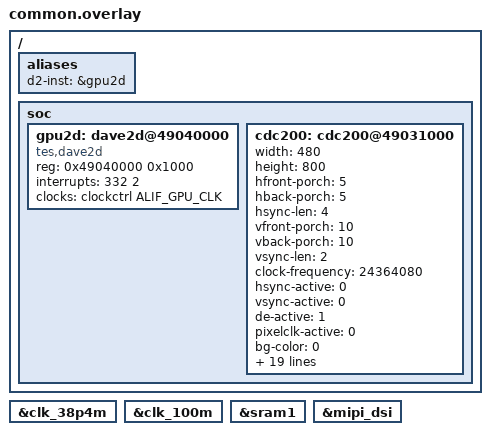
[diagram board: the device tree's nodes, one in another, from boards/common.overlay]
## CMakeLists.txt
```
# SPDX-License-Identifier: Apache-2.0

cmake_minimum_required(VERSION 3.20.0)

set(DTC_OVERLAY_FILE
    "../../../boards/arm/alif_e7_devkit/alif_e7_dk_rtss_he_hp_dave2d.overlay"
    "boards/alif_serial_display.overlay"
)

find_package(Zephyr REQUIRED HINTS $ENV{ZEPHYR_BASE})
project(aipl_example)

add_subdirectory(
    ../../../lib/aipl
    ${CMAKE_BINARY_DIR}/lib/aipl
)

# Add include directories
zephyr_include_directories(
    ../common/assets
    ../common/display/
    src/graphics/
)

# Add app sources
target_sources(app PRIVATE
    ../common/cache.c
    ../common/video_alloc.c
    ../common/display/display.c
    src/graphics/image.c
    src/main.c
)

# Link AIPL with the app
target_link_libraries(app PRIVATE aipl)

if (NOT CONFIG_AIPL_DAVE2D_ACCELERATION)
    # Add D/AVE2D functions directly to be able to use it
    target_sources(app PRIVATE ../../../lib/aipl/source/aipl_dave2d.c)
endif()

# Add asset files to the app
target_sources(app PRIVATE
    ../common/assets/sample_photo_alpha8.c
    ../common/assets/sample_photo_argb1555.c
    ../common/assets/sample_photo_argb4444.c
    ../common/assets/sample_photo_argb8888.c
    ../common/assets/sample_photo_rgb565.c
    ../common/assets/sample_photo_rgb888.c
    ../common/assets/sample_photo_rgba4444.c
    ../common/assets/sample_photo_rgba5551.c
    ../common/assets/sample_photo_rgba8888.c
)
```

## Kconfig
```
# Copyright(C) 2025 Alif Semiconductor - All Rights Reserved.
# Use, distribution and modification of this code is permitted under the
# terms stated in the Alif Semiconductor Software License Agreement
#
# You should have received a copy of the Alif Semiconductor Software
# License Agreement with this file.If not, please write to:
# contact @alifsemi.com, or visit : https: // alifsemi.com/license

source "../alif/lib/aipl/Kconfig"
source "Kconfig.zephyr"
```

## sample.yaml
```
sample:
  name: Alif Image Processing Library demo
  common:
    modules:
      - aipl
      - dave2d
```

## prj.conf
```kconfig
CONFIG_AIPL=y
CONFIG_DAVE2D=y

CONFIG_MIPI_DSI=y
CONFIG_DISPLAY=y
CONFIG_HEAP_MEM_POOL_SIZE=16384

CONFIG_MAIN_STACK_SIZE=2048

CONFIG_IMG_ASSETS=y
CONFIG_DBUF_DISPLAY=y
CONFIG_DBUF_DISPLAY_SECTION=".alif_sram0"
CONFIG_D0_HEAP_SECTION=".alif_sram1"
CONFIG_IMG_CNV_SECTION=".alif_sram0"

CONFIG_LOG=y
```

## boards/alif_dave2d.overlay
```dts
/* Copyright (C) 2024 Alif Semiconductor - All Rights Reserved.
 * Use, distribution and modification of this code is permitted under the
 * terms stated in the Alif Semiconductor Software License Agreement
 *
 * You should have received a copy of the Alif Semiconductor Software
 * License Agreement with this file. If not, please write to:
 * contact@alifsemi.com, or visit: https://alifsemi.com/license
 *
 */

/ {
	soc {
		gpu2d: dave2d@49040000 {
            compatible = "tes,dave2d";
            reg = < 0x49040000 0x1000 >;
            interrupts = < 332 2 >;
            clocks = < &clock ALIF_GPU_CLK >;
        };
	};

    aliases {
        d2-inst = &gpu2d;
    };
};
```

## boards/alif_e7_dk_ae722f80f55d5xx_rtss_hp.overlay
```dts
/* Copyright (C) Alif Semiconductor - All Rights Reserved.
 * Use, distribution and modification of this code is permitted under the
 * terms stated in the Alif Semiconductor Software License Agreement
 *
 * You should have received a copy of the Alif Semiconductor Software
 * License Agreement with this file. If not, please write to:
 * contact@alifsemi.com, or visit: https://alifsemi.com/license
 *
 */

#include "common.overlay"
```

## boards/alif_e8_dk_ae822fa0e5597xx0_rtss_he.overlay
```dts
/* Copyright (C) Alif Semiconductor - All Rights Reserved.
 * Use, distribution and modification of this code is permitted under the
 * terms stated in the Alif Semiconductor Software License Agreement
 *
 * You should have received a copy of the Alif Semiconductor Software
 * License Agreement with this file. If not, please write to:
 * contact@alifsemi.com, or visit: https://alifsemi.com/license
 *
 */

#include "common.overlay"

&gpio14 {
	status = "okay";
};
```

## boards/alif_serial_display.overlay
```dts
/* Copyright (C) 2025 Alif Semiconductor - All Rights Reserved.
 * Use, distribution and modification of this code is permitted under the
 * terms stated in the Alif Semiconductor Software License Agreement
 *
 * You should have received a copy of the Alif Semiconductor Software
 * License Agreement with this file. If not, please write to:
 * contact@alifsemi.com, or visit: https://alifsemi.com/license
 *
 */

/ {
	soc {
		cdc200: cdc200@49031000 {
			width = <480>;
			height = <800>;
			hfront-porch = <5>;
			hback-porch = <5>;
			hsync-len = <4>;
			vfront-porch = <10>;
			vback-porch = <10>;
			vsync-len = <2>;
			clock-frequency = <24364080>;
			hsync-active = <0>;
			vsync-active = <0>;
			de-active = <1>;
			pixelclk-active = <0>;
			bg-color = <0>;
			enable-l1 = <1>;
			pixel-fmt-l1 = "rgb-565";
			def-back-color-l1 = <0>;
			win-x0-l1 = <0>;
			win-y0-l1 = <0>;
			win-x1-l1 = <480>;
			win-y1-l1 = <800>;
			blend-factor1-l1 = <4>;
			blend-factor2-l1 = <5>;
			const-alpha-l1 = <0xff>;
			enable-l2 = <0>;
			pixel-fmt-l2 = "undefined";
			win-x0-l2 = <0>;
			win-y0-l2 = <0>;
			win-x1-l2 = <0>;
			win-y1-l2 = <0>;
			blend-factor1-l2 = <6>;
			blend-factor2-l2 = <7>;
			const-alpha-l2 = <0xff>;
		};
	};
};

&mipi_dsi {
	status = "okay";
};
```

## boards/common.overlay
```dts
/* Copyright (C) Alif Semiconductor - All Rights Reserved.
 * Use, distribution and modification of this code is permitted under the
 * terms stated in the Alif Semiconductor Software License Agreement
 *
 * You should have received a copy of the Alif Semiconductor Software
 * License Agreement with this file. If not, please write to:
 * contact@alifsemi.com, or visit: https://alifsemi.com/license
 *
 */

/ {
	aliases {
		d2-inst = &gpu2d;
	};

	soc {
		gpu2d: dave2d@49040000 {
			compatible = "tes,dave2d";
			reg = <0x49040000 0x1000>;
			interrupts = <332 2>;
			clocks = <&clockctrl ALIF_GPU_CLK>;
		};

		cdc200: cdc200@49031000 {
			width = <480>;
			height = <800>;
			hfront-porch = <5>;
			hback-porch = <5>;
			hsync-len = <4>;
			vfront-porch = <10>;
			vback-porch = <10>;
			vsync-len = <2>;
			clock-frequency = <24364080>;
			hsync-active = <0>;
			vsync-active = <0>;
			de-active = <1>;
			pixelclk-active = <0>;
			bg-color = <0>;
			enable-l1 = <1>;
			pixel-fmt-l1 = "rgb-565";
			def-back-color-l1 = <0>;
			win-x0-l1 = <0>;
			win-y0-l1 = <0>;
			win-x1-l1 = <480>;
			win-y1-l1 = <800>;
			blend-factor1-l1 = <4>;
			blend-factor2-l1 = <5>;
			const-alpha-l1 = <0xff>;
			enable-l2 = <0>;
			pixel-fmt-l2 = "undefined";
			win-x0-l2 = <0>;
			win-y0-l2 = <0>;
			win-x1-l2 = <0>;
			win-y1-l2 = <0>;
			blend-factor1-l2 = <6>;
			blend-factor2-l2 = <7>;
			const-alpha-l2 = <0xff>;
		};
	};
};

&clk_38p4m {
	status = "okay";
};

&clk_100m {
	status = "okay";
};

&sram1 {
	status = "okay";
};

&mipi_dsi {
	status = "okay";
};
```

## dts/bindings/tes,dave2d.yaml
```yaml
# Copyright (C) 2025 Alif Semiconductor
# SPDX-License-Identifier: Apache-2.0

description: TES D/AVE2D graphics IP core

compatible: "tes,dave2d"

include: [base.yaml]

properties:
  reg:
    required: true

  interrupts:
    required: true

  clocks:
    required: true
```

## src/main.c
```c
/* Copyright (C) Alif Semiconductor - All Rights Reserved.
 * Use, distribution and modification of this code is permitted under the
 * terms stated in the Alif Semiconductor Software License Agreement
 *
 * You should have received a copy of the Alif Semiconductor Software
 * License Agreement with this file. If not, please write to:
 * contact@alifsemi.com, or visit: https://alifsemi.com/license
 *
 */

#include <dave_d0lib.h>
#include <aipl_dave2d.h>
#include <aipl_color_conversion.h>
#include <aipl_color_correction.h>
#include <aipl_white_balance.h>
#include <aipl_lut_transform.h>
#include <aipl_crop.h>
#include <aipl_resize.h>
#include <aipl_rotate.h>
#include <aipl_flip.h>
#include <aipl_utils.h>

#include <math.h>

#include "image.h"
#include "img_assets/assets.h"
#include "dbuf_display/display.h"

#include <soc_common.h>
#include <se_service.h>

#include <zephyr/kernel.h>
#include <zephyr/drivers/gpio.h>
#include <zephyr/drivers/display.h>
#include <zephyr/logging/log.h>
LOG_MODULE_REGISTER(app, CONFIG_LOG_DEFAULT_LEVEL);

#define D1_HEAP_SIZE 0x180000

#ifdef CONFIG_D0_HEAP_SECTION
#define D0_HEAP_ATTRS __attribute__((section(CONFIG_D0_HEAP_SECTION)))
#else
#define D0_HEAP_ATTRS
#endif

static uint8_t D0_HEAP_ATTRS d0_heap[D1_HEAP_SIZE];

static void display_panel_on(void)
{
#if DT_HAS_ALIAS(panel) && DT_NODE_HAS_STATUS(DT_ALIAS(panel), okay)
	const struct device *panel = DEVICE_DT_GET(DT_ALIAS(panel));

	if (!device_is_ready(panel)) {
		LOG_WRN("Display panel device not ready");
		return;
	}

	int ret = display_blanking_off(panel);

	if (ret) {
		LOG_WRN("Display panel enable failed (%d), continuing", ret);
	}
#endif
}

static void crop_scale_example(void)
{
	/* Prepare the source image */
	const image_t *test_img = &SAMPLE_PHOTO_ARGB8888;
	const aipl_image_t src_image = {test_img->data, test_img->pitch, test_img->width,
					test_img->height, test_img->format};

	/* Prepare the destination image for cropping */
	uint32_t p = src_image.pitch / 4;
	uint32_t w = src_image.width / 4;
	uint32_t h = src_image.height / 4;
	aipl_image_t cropped_image;

	aipl_image_create(&cropped_image, p, w, h, src_image.format);

	/* Crop the source image using the specified rectangular area */
	uint32_t x = 200;
	uint32_t y = 100;

	aipl_crop_img(&src_image, &cropped_image, x, y, x + w, y + h);

	/* Prepare the destination image for scaling */
	aipl_image_t scaled_image;

	aipl_image_create(&scaled_image, p * 3, w * 3, h * 3, cropped_image.format);

	/* Scale up the cropped image appliying linear interpolation */
	aipl_resize_img(&cropped_image, &scaled_image, true);

	/* Prepare DAVE2D for image rendering */
	aipl_dave2d_prepare();

	/* Draw source and destination images */
	aipl_image_draw(0, 20, &src_image);
	aipl_image_draw(0, 400, &cropped_image);
	aipl_image_draw(0, 500, &scaled_image);

	/* Execute HW rendering */
	aipl_dave2d_render();

	/* Release the memory occupied by the destination images */
	aipl_image_destroy(&cropped_image);
	aipl_image_destroy(&scaled_image);
}

static void crop_flip_example(void)
{
	/* Prepare the source image */
	const image_t *test_img = &SAMPLE_PHOTO_ARGB8888;
	const aipl_image_t src_image = {test_img->data, test_img->pitch, test_img->width,
					test_img->height, test_img->format};

	/* Prepare the destination image for cropping */
	uint32_t p = src_image.pitch / 2;
	uint32_t w = src_image.width / 2;
	uint32_t h = src_image.height / 2;
	aipl_image_t cropped_image;

	aipl_image_create(&cropped_image, p, w, h, src_image.format);

	/* Crop the source image using the specified rectangular area */
	uint32_t x = 200;
	uint32_t y = 100;

	aipl_crop_img(&src_image, &cropped_image, x, y, x + w, y + h);

	/* Prepare the destination image for flipping */
	aipl_image_t flipped_image;

	aipl_image_create(&flipped_image, p, w, h, cropped_image.format);

	/* Flip the image horizontally and vertically */
	aipl_flip_img(&cropped_image, &flipped_image, true, true);

	/* Prepare DAVE2D for image rendering */
	aipl_dave2d_prepare();

	/* Draw source and destination images */
	aipl_image_draw(0, 20, &src_image);
	aipl_image_draw(0, 400, &cropped_image);
	aipl_image_draw(0, 600, &flipped_image);

	/* Execute HW rendering */
	aipl_dave2d_render();

	/* Release the memory occupied by the destination images */
	aipl_image_destroy(&cropped_image);
	aipl_image_destroy(&flipped_image);
}

static void scale_rotate_example(void)
{
	/* Prepare the source image */
	const image_t *test_img = &SAMPLE_PHOTO_ARGB8888;
	const aipl_image_t src_image = {test_img->data, test_img->pitch, test_img->width,
					test_img->height, test_img->format};

	/* Prepare the destination image for scaling */
	uint32_t p = src_image.pitch / 2;
	uint32_t w = src_image.width / 2;
	uint32_t h = src_image.height / 2;
	aipl_image_t scaled_image;

	aipl_image_create(&scaled_image, p, w, h, src_image.format);

	/* Scale down the source image using nearest-neighbor interpolation */
	aipl_resize_img(&src_image, &scaled_image, false);

	/* Prepare the destination image for rotation */
	aipl_image_t rotated90_image;

	aipl_image_create(&rotated90_image, h, h, w, src_image.format);
	aipl_image_t rotated180_image;

	aipl_image_create(&rotated180_image, p, w, h, src_image.format);

	/* Scale down the image */
	aipl_rotate_img(&scaled_image, &rotated90_image, AIPL_ROTATE_90);
	aipl_rotate_img(&scaled_image, &rotated180_image, AIPL_ROTATE_180);

	/* Prepare DAVE2D for image rendering */
	aipl_dave2d_prepare();

	/* Draw source and destination images */
	aipl_image_draw(0, 20, &src_image);
	aipl_image_draw(0, 400, &scaled_image);
	aipl_image_draw(300, 400, &rotated90_image);
	aipl_image_draw(0, 600, &rotated180_image);

	/* Execute HW rendering */
	aipl_dave2d_render();

	/* Release the memory occupied by the destination images */
	aipl_image_destroy(&scaled_image);
	aipl_image_destroy(&rotated90_image);
	aipl_image_destroy(&rotated180_image);
}

/* Example of conversion from ARGB8888 to ALPHA8 */
static void color_conversion_example(void)
{
	/* Prepare the source image */
	const image_t *test_img = &SAMPLE_PHOTO_ARGB8888;
	const aipl_image_t src_image = {test_img->data, test_img->pitch, test_img->width,
					test_img->height, test_img->format};

	/* Prepare the destination buffer for converted image */
	aipl_image_t dst_image;

	aipl_image_create(&dst_image, src_image.pitch, src_image.width, src_image.height,
			  AIPL_COLOR_ALPHA8);

	/* Peform the conversion */
	aipl_color_convert_img(&src_image, &dst_image);

	/* Prepare DAVE2D for image rendering */
	aipl_dave2d_prepare();

	/* Draw source and destination images */
	aipl_image_draw(0, 20, &src_image);
	aipl_image_draw(0, 400, &dst_image);

	/* Execute HW rendering */
	aipl_dave2d_render();

	/* Release the memory occupied by the destination images */
	aipl_image_destroy(&dst_image);
}

/* Example of color correction to increase color saturation */
static void color_correction_example(void)
{
	/* Prepare the source image */
	const image_t *test_img = &SAMPLE_PHOTO_ARGB8888;
	const aipl_image_t src_image = {test_img->data, test_img->pitch, test_img->width,
					test_img->height, test_img->format};

	/* Prepare the destination color corrected image */
	aipl_image_t dst_image;

	aipl_image_create(&dst_image, src_image.pitch, src_image.width, src_image.height,
			  src_image.format);

	/* Prepare color correction matrix */
	static float ccm[] = {1.3f, -0.3f, -0.3f, -0.3f, 1.3f, -0.3f, -0.3f, -0.3f, 1.3f};

	/* Peform the correction */
	aipl_color_correction_rgb_img(&src_image, &dst_image, ccm);

	/* Prepare DAVE2D for image rendering */
	aipl_dave2d_prepare();

	/* Draw source and destination images */
	aipl_image_draw(0, 20, &src_image);
	aipl_image_draw(0, 400, &dst_image);

	/* Execute HW rendering */
	aipl_dave2d_render();

	/* Release the memory occupied by the destination images */
	aipl_image_destroy(&dst_image);
}

/* Example of using white balance to add a blueish tint */
static void white_balance_example(void)
{
	/* Prepare the source image */
	const image_t *test_img = &SAMPLE_PHOTO_ARGB8888;
	const aipl_image_t src_image = {test_img->data, test_img->pitch, test_img->width,
					test_img->height, test_img->format};

	/* Prepare the destination white balanced image */
	aipl_image_t dst_image;

	aipl_image_create(&dst_image, src_image.pitch, src_image.width, src_image.height,
			  src_image.format);

	/* Peform the correction */
	aipl_white_balance_rgb_img(&src_image, &dst_image, 1.0f, 0.8f, 1.2f);

	/* Prepare DAVE2D for image rendering */
	aipl_dave2d_prepare();

	/* Draw source and destination images */
	aipl_image_draw(0, 20, &src_image);
	aipl_image_draw(0, 400, &dst_image);

	/* Execute HW rendering */
	aipl_dave2d_render();

	/* Release the memory occupied by the destination images */
	aipl_image_destroy(&dst_image);
}

/* Example of gamma correction from sRGB to linear */
static void gamma_correction_example(void)
{
	/* Prepare the source image */
	const image_t *test_img = &SAMPLE_PHOTO_ARGB8888;
	const aipl_image_t src_image = {test_img->data, test_img->pitch, test_img->width,
					test_img->height, test_img->format};

	/* Prepare the destination color corrected image */
	aipl_image_t dst_image;

	aipl_image_create(&dst_image, src_image.pitch, src_image.width, src_image.height,
			  src_image.format);

	/* Prepare gamma correction LUT */
	static uint8_t lut[256];

	for (uint32_t i = 0; i < 256; ++i) {
		float srgb_num = i * (1.0f / 255.0f);

		float lin_num;

		if (srgb_num <= 0.04045f) {
			lin_num = srgb_num / 12.92f;
		} else {
			lin_num = powf((double)(srgb_num + 0.055f) / 1.055, 2.4f);
		}

		lut[i] = lin_num * 255.0f + 0.5f;
	}

	/* Peform the gamma LUT transform */
	aipl_lut_transform_rgb_img(&src_image, &dst_image, lut);

	/* Prepare DAVE2D for image rendering */
	aipl_dave2d_prepare();

	/* Draw source and destination images */
	aipl_image_draw(0, 20, &src_image);
	aipl_image_draw(0, 400, &dst_image);

	/* Execute HW rendering */
	aipl_dave2d_render();

	/* Release the memory occupied by the destination images */
	aipl_image_destroy(&dst_image);
}

/* Example of exposure adjustment */
static void exposure_adjustment_example(void)
{
	/* Prepare the source image */
	const image_t *test_img = &SAMPLE_PHOTO_ARGB8888;
	const aipl_image_t src_image = {test_img->data, test_img->pitch, test_img->width,
					test_img->height, test_img->format};

	/* Prepare the destination color corrected image */
	aipl_image_t dst_image;

	aipl_image_create(&dst_image, src_image.pitch, src_image.width, src_image.height,
			  src_image.format);

	/* Prepare exposure adjustment LUT */
	float exp_adj = 0.5f;
	static uint8_t lut[256];

	for (uint32_t i = 0; i < 256; ++i) {
		lut[i] = aipl_channel_cap((int)(i * powf(2, exp_adj)));
	}

	/* Peform the exposure LUT transform */
	aipl_lut_transform_rgb_img(&src_image, &dst_image, lut);

	/* Prepare DAVE2D for image rendering */
	aipl_dave2d_prepare();

	/* Draw source and destination images */
	aipl_image_draw(0, 20, &src_image);
	aipl_image_draw(0, 400, &dst_image);

	/* Execute HW rendering */
	aipl_dave2d_render();

	/* Release the memory occupied by the destination images */
	aipl_image_destroy(&dst_image);
}

int main(void)
{
	/* Initialize display */
	if (display_init()) {
		LOG_ERR("Display initializing error");
		return -1;
	}
	display_panel_on();

#ifdef CONFIG_D1_MALLOC_D0LIB
	/* Initialize D/AVE D0 heap */
	if (!d0_initheapmanager(d0_heap, sizeof(d0_heap), d0_mm_fixed_range, NULL, 0, 0, 0,
				d0_ma_unified)) {
		LOG_ERR("Heap manager initialization failed");
		return -1;
	}
#endif

	/* Initialize D/AVE2D */
	if (aipl_dave2d_init() != D2_OK) {
		LOG_ERR("D/AVE2D initialization failed");
		return -1;
	}

	/* Run AIPL examples */
	while (true) {
		LOG_INF("Example 1: Crop the image and scale it up");
		crop_scale_example();
		k_msleep(3000);
		LOG_INF("Example 2: Scale down the image and rotate 90/180 degrees");
		scale_rotate_example();
		k_msleep(3000);
		LOG_INF("Example 3: Crop the image and flip it both vertically and horizontally");
		crop_flip_example();
		k_msleep(3000);
		LOG_INF("Example 4: Convert ARGB8888 to ALPHA8");
		color_conversion_example();
		k_msleep(3000);
		LOG_INF("Example 5: Increase color saturation (color correction)");
		color_correction_example();
		k_msleep(3000);
		LOG_INF("Example 6: Use white balance to add a blueish tint");
		white_balance_example();
		k_msleep(3000);
		LOG_INF("Example 7: Gamma correction from sRGB to linear");
		gamma_correction_example();
		k_msleep(3000);
		LOG_INF("Example 8: Exposure adjustment");
		exposure_adjustment_example();
		k_msleep(5000);
	}

	return 0;
}

/*
 * Do application configurations.
 */
static int app_set_parameters(void)
{
	int ret;
	run_profile_t runp = (run_profile_t){0};

#if (defined(CONFIG_ENSEMBLE_GEN2) && defined(CONFIG_MIPI_DSI))
	const struct gpio_dt_spec cam_disp_mux_gpio =
		GPIO_DT_SPEC_GET(DT_NODELABEL(mipi_dsi), cam_disp_mux_gpios);
	gpio_pin_configure_dt(&cam_disp_mux_gpio, GPIO_OUTPUT_ACTIVE);
#endif

	runp.power_domains = PD_SYST_MASK | PD_SSE700_AON_MASK | PD_DBSS_MASK;
	runp.dcdc_voltage  = 825;
	runp.dcdc_mode     = DCDC_MODE_PWM;
	runp.aon_clk_src   = CLK_SRC_LFXO;
	runp.run_clk_src   = CLK_SRC_PLL;
	runp.vdd_ioflex_3V3 = IOFLEX_LEVEL_1V8;
#if defined(CONFIG_RTSS_HP)
	runp.cpu_clk_freq  = CLOCK_FREQUENCY_400MHZ;
#else
	runp.cpu_clk_freq  = CLOCK_FREQUENCY_160MHZ;
#endif

	runp.memory_blocks = MRAM_MASK;
#if DT_NODE_EXISTS(DT_NODELABEL(sram0))
	runp.memory_blocks |= SRAM0_MASK;
#endif
#if DT_NODE_EXISTS(DT_NODELABEL(sram1))
	runp.memory_blocks |= SRAM1_MASK;
#endif

	runp.phy_pwr_gating |= MIPI_TX_DPHY_MASK | MIPI_RX_DPHY_MASK |
		MIPI_PLL_DPHY_MASK | LDO_PHY_MASK;
	runp.ip_clock_gating = CDC200_MASK | MIPI_CSI_MASK | MIPI_DSI_MASK |
		GPU_MASK;

	ret = se_service_set_run_cfg(&runp);
	__ASSERT(ret == 0, "SE: set_run_cfg failed = %d", ret);

	return ret;
}

SYS_INIT(app_set_parameters, PRE_KERNEL_1, 46);
```
